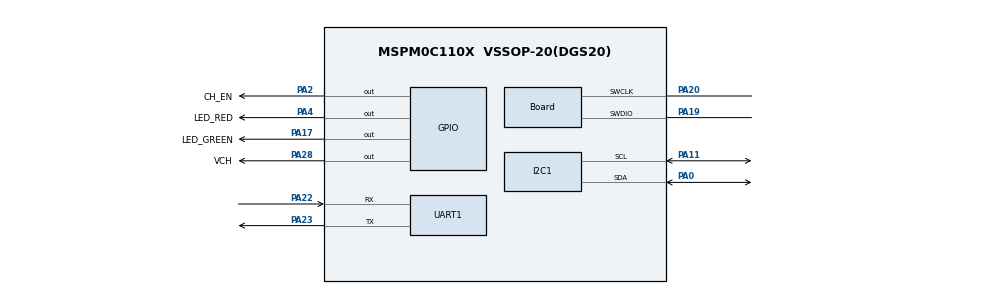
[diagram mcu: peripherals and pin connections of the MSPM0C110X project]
/**
 * @cliArgs --device "MSPM0C110X" --part "Default" --package "VSSOP-20(DGS20)" --product "mspm0_sdk@2.03.00.07"
 * @versions {"tool":"1.21.0+3721"}
 */

/**
 * Import the modules used in this configuration.
 */
const ADC12         = scripting.addModule("/ti/driverlib/ADC12", {}, false);
const ADC121        = ADC12.addInstance();
const Board         = scripting.addModule("/ti/driverlib/Board");
const GPIO          = scripting.addModule("/ti/driverlib/GPIO", {}, false);
const GPIO1         = GPIO.addInstance();
const I2C           = scripting.addModule("/ti/driverlib/I2C", {}, false);
const I2C1          = I2C.addInstance();
const SYSCTL        = scripting.addModule("/ti/driverlib/SYSCTL");
const TIMER         = scripting.addModule("/ti/driverlib/TIMER", {}, false);
const TIMER1        = TIMER.addInstance();
const UART          = scripting.addModule("/ti/driverlib/UART", {}, false);
const UART1         = UART.addInstance();
const ProjectConfig = scripting.addModule("/ti/project_config/ProjectConfig");

/**
 * Write custom configuration values to the imported modules.
 */
ADC121.$name                      = "ADC12_0";
ADC121.sampClkDiv                 = "DL_ADC12_CLOCK_DIVIDE_8";
ADC121.samplingOperationMode      = "sequence";
ADC121.endAdd                     = 3;
ADC121.sampClkSrc                 = "DL_ADC12_CLOCK_ULPCLK";
ADC121.powerDownMode              = "DL_ADC12_POWER_DOWN_MODE_MANUAL";
ADC121.sampleTime0                = "1 ms";
ADC121.enabledInterrupts          = ["DL_ADC12_INTERRUPT_MEM3_RESULT_LOADED"];
ADC121.adcMem1chansel             = "DL_ADC12_INPUT_CHAN_8";
ADC121.adcMem2chansel             = "DL_ADC12_INPUT_CHAN_3";
ADC121.adcMem3chansel             = "DL_ADC12_INPUT_CHAN_2";
ADC121.peripheral.$assign         = "ADC0";
ADC121.peripheral.adcPin0.$assign = "PA27";
ADC121.peripheral.adcPin8.$assign = "PA16";
ADC121.peripheral.adcPin3.$assign = "PA24";
ADC121.peripheral.adcPin2.$assign = "PA25";
ADC121.adcPin0Config.$name        = "ti_driverlib_gpio_GPIOPinGeneric2";
ADC121.adcPin8Config.$name        = "ti_driverlib_gpio_GPIOPinGeneric3";
ADC121.adcPin3Config.$name        = "ti_driverlib_gpio_GPIOPinGeneric4";
ADC121.adcPin2Config.$name        = "ti_driverlib_gpio_GPIOPinGeneric5";

Board.InitPriority15              = "/ti/driverlib/ADC12";
Board.peripheral.$assign          = "DEBUGSS";
Board.peripheral.swclkPin.$assign = "PA20";
Board.peripheral.swdioPin.$assign = "PA19";

GPIO1.$name                                 = "BAMBOO_GPIO";
GPIO1.associatedPins.create(6);
GPIO1.associatedPins[0].initialValue        = "SET";
GPIO1.associatedPins[0].ioStructure         = "SD";
GPIO1.associatedPins[0].assignedPort        = "PORTA";
GPIO1.associatedPins[0].assignedPortSegment = "Upper";
GPIO1.associatedPins[0].$name               = "LED_GREEN";
GPIO1.associatedPins[0].assignedPin         = "17";
GPIO1.associatedPins[0].pin.$assign         = "PA17";
GPIO1.associatedPins[1].initialValue        = "SET";
GPIO1.associatedPins[1].ioStructure         = "SD";
GPIO1.associatedPins[1].assignedPort        = "PORTA";
GPIO1.associatedPins[1].assignedPortSegment = "Lower";
GPIO1.associatedPins[1].$name               = "LED_RED";
GPIO1.associatedPins[1].assignedPin         = "4";
GPIO1.associatedPins[1].pin.$assign         = "PA4";
GPIO1.associatedPins[2].$name               = "CH_EN";
GPIO1.associatedPins[2].initialValue        = "SET";
GPIO1.associatedPins[2].ioStructure         = "SD";
GPIO1.associatedPins[2].assignedPort        = "PORTA";
GPIO1.associatedPins[2].assignedPin         = "2";
GPIO1.associatedPins[2].pin.$assign         = "PA2";
GPIO1.associatedPins[3].$name               = "BS_EN";
GPIO1.associatedPins[3].initialValue        = "SET";
GPIO1.associatedPins[3].ioStructure         = "SD";
GPIO1.associatedPins[3].assignedPort        = "PORTA";
GPIO1.associatedPins[3].assignedPortSegment = "Lower";
GPIO1.associatedPins[3].assignedPin         = "6";
GPIO1.associatedPins[4].$name               = "ACOK";
GPIO1.associatedPins[4].assignedPort        = "PORTA";
GPIO1.associatedPins[4].assignedPortSegment = "Upper";
GPIO1.associatedPins[4].assignedPin         = "18";
GPIO1.associatedPins[4].ioStructure         = "SD";
GPIO1.associatedPins[5].ioStructure         = "SD";
GPIO1.associatedPins[5].initialValue        = "SET";
GPIO1.associatedPins[5].$name               = "VCH";
GPIO1.associatedPins[5].assignedPort        = "PORTA";
GPIO1.associatedPins[5].assignedPin         = "28";
GPIO1.associatedPins[5].assignedPortSegment = "Upper";
GPIO1.associatedPins[5].pin.$assign         = "PA28";

I2C1.$name                             = "I2C";
I2C1.basicEnableController             = true;
I2C1.basicControllerBusSpeed           = 400000;
I2C1.advAnalogGlitchFilter             = "DISABLED";
I2C1.peripheral.$assign                = "I2C0";
I2C1.peripheral.sdaPin.$assign         = "PA0";
I2C1.peripheral.sclPin.$assign         = "PA11";
I2C1.sdaPinConfig.hideOutputInversion  = scripting.forceWrite(false);
I2C1.sdaPinConfig.onlyInternalResistor = scripting.forceWrite(false);
I2C1.sdaPinConfig.passedPeripheralType = scripting.forceWrite("Digital");
I2C1.sdaPinConfig.$name                = "ti_driverlib_gpio_GPIOPinGeneric0";
I2C1.sclPinConfig.hideOutputInversion  = scripting.forceWrite(false);
I2C1.sclPinConfig.onlyInternalResistor = scripting.forceWrite(false);
I2C1.sclPinConfig.passedPeripheralType = scripting.forceWrite("Digital");
I2C1.sclPinConfig.$name                = "ti_driverlib_gpio_GPIOPinGeneric1";

SYSCTL.clockTreeEn = true;

TIMER1.$name               = "TIMER_0";
TIMER1.timerClkSrc         = "LFCLK";
TIMER1.enableRepeatCounter = true;
TIMER1.interrupts          = ["REPC"];
TIMER1.timerMode           = "PERIODIC";
TIMER1.timerPeriod         = "50ms";
TIMER1.repeatCounter       = 2;

UART1.$name                        = "UART_0";
UART1.enabledInterrupts            = ["RX"];
UART1.peripheral.rxPin.$assign     = "PA22";
UART1.peripheral.txPin.$assign     = "PA23";
UART1.txPinConfig.$name            = "ti_driverlib_gpio_GPIOPinGeneric6";
UART1.rxPinConfig.$name            = "ti_driverlib_gpio_GPIOPinGeneric7";
UART1.rxPinConfig.enableConfig     = true;
UART1.rxPinConfig.internalResistor = "PULL_UP";

ProjectConfig.deviceSpin = "MSPM0C1104";
ProjectConfig.genLinker  = false;

/**
 * Pinmux solution for unlocked pins/peripherals. This ensures that minor changes to the automatic solver in a future
 * version of the tool will not impact the pinmux you originally saw.  These lines can be completely deleted in order to
 * re-solve from scratch.
 */
GPIO1.associatedPins[3].pin.$suggestSolution = "PA6";
GPIO1.associatedPins[4].pin.$suggestSolution = "PA18";
TIMER1.peripheral.$suggestSolution           = "TIMA0";
UART1.peripheral.$suggestSolution            = "UART0";
